# ESP32-C3 register map
Vendor: ESPRESSIF SYSTEMS (SHANGHAI) CO., LTD.; Series: ESP32 C-Series; File version: 19
CPU: RV32IMC r0p0, little endian, no MPU, no FPU, 0 interrupt priority bits
Address unit: 32 bits
Registers are 32-bit, read-write, reset 0x0 unless marked. A register's access mark holds for its fields unless they carry their own. Offsets are from the block's base; [hi:lo] are bit positions; {n}, {i} and the like mark numbered series.

## AES — AES (Advanced Encryption Standard) Accelerator
Base 0x6003A000
{0x0+4i} KEY_{i} (i=0..7) — Key material key_{i} configure register
  [31:0] KEY_{i} — This bits stores key_{i} that is a part of key material.
{0x20+4i} TEXT_IN_{i} (i=0..3) — source text material text_in_{i} configure register
  [31:0] TEXT_IN_{i} — This bits stores text_in_{i} that is a part of source text material.
{0x30+4i} TEXT_OUT_{i} (i=0..3) — result text material text_out_{i} configure register
  [31:0] TEXT_OUT_{i} — This bits stores text_out_{i} that is a part of result text material.
0x40 MODE — AES Mode register
  [2:0] MODE — This bits decides which one operation mode will be used. 3'd0: AES-EN-128, 3'd1: AES-EN-192, 3'd2: AES-EN-256, 3'd4: AES-DE-128, 3'd5: AES-DE-192, 3'd6: AES-DE-256.
0x44 ENDIAN — AES Endian configure register
  [5:0] ENDIAN — endian. [1:0] key endian, [3:2] text_in endian or in_stream endian, [5:4] text_out endian or out_stream endian
0x48 TRIGGER wo — AES trigger register
  [0] TRIGGER — Set this bit to start AES calculation.
0x4C STATE ro — AES state register
  [1:0] STATE — Those bits shows AES status. For typical AES, 0: idle, 1: busy. For DMA-AES, 0: idle, 1: busy, 2: calculation_done.
{0x50+i} IV_MEM[{i}] (i=0..15) 8-bit access not given — The memory that stores initialization vector
{0x60+i} H_MEM[{i}] (i=0..15) 8-bit access not given — The memory that stores GCM hash subkey
{0x70+i} J0_MEM[{i}] (i=0..15) 8-bit access not given — The memory that stores J0
{0x80+i} T0_MEM[{i}] (i=0..15) 8-bit access not given — The memory that stores T0
0x90 DMA_ENABLE — DMA-AES working mode register
  [0] DMA_ENABLE — 1'b0: typical AES working mode, 1'b1: DMA-AES working mode.
0x94 BLOCK_MODE — AES cipher block mode register
  [2:0] BLOCK_MODE — Those bits decides which block mode will be used. 0x0: ECB, 0x1: CBC, 0x2: OFB, 0x3: CTR, 0x4: CFB-8, 0x5: CFB-128, 0x6: GCM, 0x7: reserved.
0x98 BLOCK_NUM — AES block number register
  [31:0] BLOCK_NUM — Those bits stores the number of Plaintext/ciphertext block.
0x9C INC_SEL — Standard incrementing function configure register
  [0] INC_SEL — This bit decides the standard incrementing function. 0: INC32. 1: INC128.
0xA0 AAD_BLOCK_NUM — Additional Authential Data block number register
  [31:0] AAD_BLOCK_NUM — Those bits stores the number of AAD block.
0xA4 REMAINDER_BIT_NUM — AES remainder bit number register
  [6:0] REMAINDER_BIT_NUM — Those bits stores the number of remainder bit.
0xA8 CONTINUE wo — AES continue register
  [0] CONTINUE — Set this bit to continue GCM operation.
0xAC INT_CLEAR wo — AES Interrupt clear register
  [0] INT_CLEAR — Set this bit to clear the AES interrupt.
0xB0 INT_ENA — AES Interrupt enable register
  [0] INT_ENA — Set this bit to enable interrupt that occurs when DMA-AES calculation is done.
0xB4 DATE reset 0x20191210 — AES version control register
  [29:0] DATE — This bits stores the version information of AES.
0xB8 DMA_EXIT wo — AES-DMA exit config
  [0] DMA_EXIT — Set this register to leave calculation done stage. Recommend to use it after software finishes reading DMA's output buffer.

## BB — BB Peripheral
Base 0x6001D000
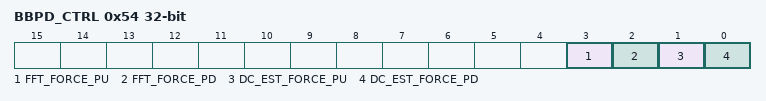
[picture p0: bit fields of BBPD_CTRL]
0x54 BBPD_CTRL — Baseband control register
  [3] FFT_FORCE_PU, [2] FFT_FORCE_PD, [1] DC_EST_FORCE_PU, [0] DC_EST_FORCE_PD

## DS — Digital Signature
Base 0x6003D000
{0x0+i} C_MEM[{i}] (i=0..1583) 8-bit access not given — memory that stores C
{0x0+i} Y_MEM[{i}] (i=0..511) 8-bit access not given — memory that stores Y
{0x200+i} M_MEM[{i}] (i=0..511) 8-bit access not given — memory that stores M
{0x400+i} RB_MEM[{i}] (i=0..511) 8-bit access not given — memory that stores Rb
{0x600+i} BOX_MEM[{i}] (i=0..47) 8-bit access not given — memory that stores BOX
{0x630+i} IV_MEM[{i}] (i=0..15) 8-bit access not given — memory that stores IV
{0x800+i} X_MEM[{i}] (i=0..511) 8-bit access not given — memory that stores X
{0xA00+i} Z_MEM[{i}] (i=0..511) 8-bit access not given — memory that stores Z
0xE00 SET_START wo — DS start control register
  [0] SET_START — set this bit to start DS operation.
0xE04 SET_CONTINUE wo — DS continue control register
  [0] SET_CONTINUE — set this bit to continue DS operation.
0xE08 SET_FINISH wo — DS finish control register
  [0] SET_FINISH — Set this bit to finish DS process.
0xE0C QUERY_BUSY ro — DS query busy register
  [0] QUERY_BUSY — digital signature state. 1'b0: idle, 1'b1: busy
0xE10 QUERY_KEY_WRONG ro — DS query key-wrong counter register
  [3:0] QUERY_KEY_WRONG — digital signature key wrong counter
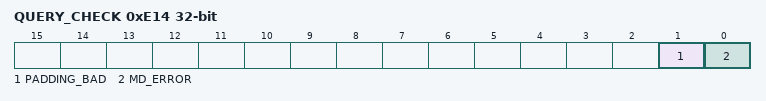
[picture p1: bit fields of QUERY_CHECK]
0xE14 QUERY_CHECK ro — DS query check result register
  [1] PADDING_BAD — padding checkout result. 1'b0: a good padding, 1'b1: a bad padding
  [0] MD_ERROR — MD checkout result. 1'b0: MD check pass, 1'b1: MD check fail
0xE20 DATE reset 0x20200618 — DS version control register
  [29:0] DATE — ds version information
